# ATSAM4NxC register map
Vendor: Atmel; Series: SAM4N; File version: 0
Atmel ATSAM4NxC Microcontroller
CPU: CM4 r0p1, selectable endian, MPU, no FPU, 4 interrupt priority bits
Registers are 32-bit, read-write, reset 0x0 unless marked. A register's access mark holds for its fields unless they carry their own. Offsets are from the block's base; lines under a group give offsets from that group; [hi:lo] are bit positions; {n}, {i} and the like mark numbered series; 'fields as' and 'values as' point back to an identical list; <NAME> marks a mode.

## Memory map
0x40008000 SPI size 0x4000 — Serial Peripheral Interface
0x4000D000 MPU size 0x830 — Memory Protection Unit (MPU)
0x40010000 TC0 size 0x4000 — Timer Counter 0
0x40014000 TC1 size 0x4000 — Timer Counter 1
0x40018000 TWI0 size 0x4000 — Two-wire Interface 0
0x4001C000 TWI1 size 0x4000 — Two-wire Interface 1
0x40020000 PWM size 0x4000 — Pulse Width Modulation Controller
0x40024000 USART0 size 0x4000 — Universal Synchronous Asynchronous Receiver Transmitter 0
0x40028000 USART1 size 0x4000 — Universal Synchronous Asynchronous Receiver Transmitter 1
0x4002C000 USART2 size 0x4000 — Universal Synchronous Asynchronous Receiver Transmitter 2
0x40038000 ADC size 0x4000 — Analog-to-Digital Converter
0x4003C000 DACC size 0x4000 — Digital-to-Analog Converter Controller
0x40040000 TWI2 size 0x4000 — Two-wire Interface 2
0x40044000 UART2 size 0x4000 — Universal Asynchronous Receiver Transmitter 2
0x40048000 UART3 size 0x4000 — Universal Asynchronous Receiver Transmitter 3
0x400E0200 MATRIX size 0x200 — AHB Bus Matrix
0x400E0400 PMC size 0x140 — Power Management Controller
0x400E0600 UART0 size 0x128 — Universal Asynchronous Receiver Transmitter 0
0x400E0740 CHIPID size 0x200 — Chip Identifier
0x400E0800 UART1 size 0x128 — Universal Asynchronous Receiver Transmitter 1
0x400E0A00 EFC size 0x200 — Embedded Flash Controller
0x400E0E00 PIOA size 0x200 — Parallel Input/Output Controller A
0x400E1000 PIOB size 0x200 — Parallel Input/Output Controller B
0x400E1200 PIOC size 0x200 — Parallel Input/Output Controller C
0x400E1400 RSTC size 0x200 — Reset Controller
0x400E1410 SUPC size 0x200 — Supply Controller
0x400E1430 RTT size 0x200 — Real-time Timer
0x400E1450 WDT size 0x200 — Watchdog Timer
0x400E1460 RTC size 0x200 — Real-time Clock
0x400E1490 GPBR size 0x200 — General Purpose Backup Registers
0xE000E000 SCB blocks up to offset 0xD40 — System Control Block (SCB)
0xE000E010 SYST size 0x10 — System timer, SysTick
0xE000E100 NVIC size 0xE04 — Nested Vectored Interrupt Controller (NVIC)

## Interrupts
3 INT_Hard_Fault (SCB)
4 INT_Mem_Manage_Fault (SCB)
5 INT_Bus_Fault (SCB)
5 PMC
6 EFC
6 INT_Usage_Fault (SCB)
8 UART0
9 UART1
10 UART2
11 INT_SVCall (SCB)
11 PIOA
12 PIOB
13 PIOC
14 INT_PendableSrvReq (SCB)
14 USART0
15 INT_SysTick (SYST)
15 USART1
16 UART3
17 USART2
19 TWI0
20 TWI1
21 SPI
22 TWI2
23 TC0
24 TC1 (TC0)
25 TC2 (TC0)
26 TC3 (TC1)
27 TC4 (TC1)
28 TC5 (TC1)
29 ADC
30 DACC
31 PWM

## PWM — Pulse Width Modulation Controller
Base 0x40020000; register names take the prefix PWM_
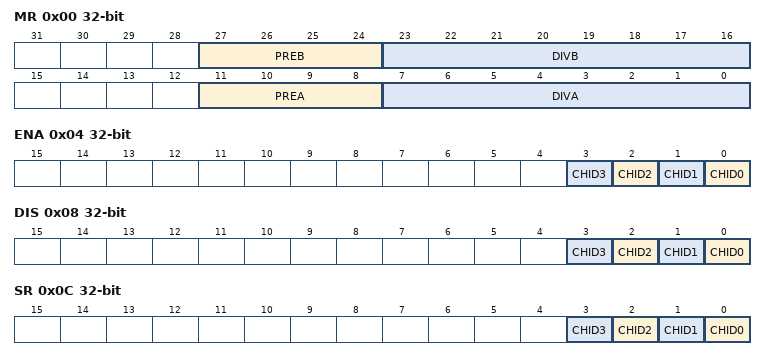
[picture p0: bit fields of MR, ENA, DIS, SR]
0x00 MR — PWM Mode Register
  [27:24] PREB
    0=MCK (Master Clock); 1=MCKDIV2 (Master Clock divided by 2); 2=MCKDIV4 (Master Clock divided by 4); 3=MCKDIV8 (Master Clock divided by 8); 4=MCKDIV16 (Master Clock divided by 16); 5=MCKDIV32 (Master Clock divided by 32); 6=MCKDIV64 (Master Clock divided by 64); 7=MCKDIV128 (Master Clock divided by 128); 8=MCKDIV256 (Master Clock divided by 256); 9=MCKDIV512 (Master Clock divided by 512); 10=MCKDIV1024 (Master Clock divided by 1024)
  [23:16] DIVB — CLKA, CLKB Divide Factor
    0=CLK_OFF (CLKA, CLKB clock is turned off); 1=CLK_DIV1 (CLKA, CLKB clock is clock selected by PREA, PREB)
  [11:8] PREA
    values as PREB
  [7:0] DIVA — CLKA, CLKB Divide Factor
    values as DIVB
0x04 ENA wo reset not defined — PWM Enable Register
  [n] CHID{n} (n=0..3) — Channel ID
0x08 DIS wo reset not defined — PWM Disable Register
  [n] CHID{n} (n=0..3) — Channel ID
0x0C SR ro — PWM Status Register
  [n] CHID{n} (n=0..3) — Channel ID
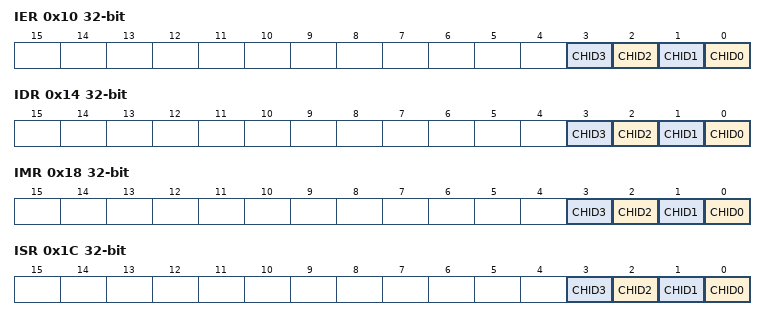
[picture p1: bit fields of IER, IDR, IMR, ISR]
0x10 IER wo reset not defined — PWM Interrupt Enable Register
  [n] CHID{n} (n=0..3) — Channel ID.
0x14 IDR wo reset not defined — PWM Interrupt Disable Register
  [n] CHID{n} (n=0..3) — Channel ID.
0x18 IMR ro — PWM Interrupt Mask Register
  [n] CHID{n} (n=0..3) — Channel ID.
0x1C ISR ro — PWM Interrupt Status Register
  [n] CHID{n} (n=0..3) — Channel ID
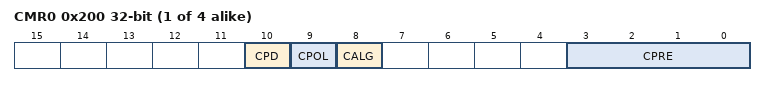
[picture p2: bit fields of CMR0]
{0x200+0x20*i} CMR{i} (i=0..3) — PWM Channel Mode Register (ch_num = {i})
  [10] CPD — Channel Update Period
  [9] CPOL — Channel Polarity
  [8] CALG — Channel Alignment
  [3:0] CPRE — Channel Pre-scaler
    0=MCK (Master Clock); 1=MCKDIV2 (Master Clock divided by 2); 2=MCKDIV4 (Master Clock divided by 4); 3=MCKDIV8 (Master Clock divided by 8); 4=MCKDIV16 (Master Clock divided by 16); 5=MCKDIV32 (Master Clock divided by 32); 6=MCKDIV64 (Master Clock divided by 64); 7=MCKDIV128 (Master Clock divided by 128); 8=MCKDIV256 (Master Clock divided by 256); 9=MCKDIV512 (Master Clock divided by 512); 10=MCKDIV1024 (Master Clock divided by 1024); 11=CLKA (Clock A); 12=CLKB (Clock B)
{0x204+0x20*i} CDTY{i} (i=0..3) — PWM Channel Duty Cycle Register (ch_num = {i})
  [31:0] CDTY — Channel Duty Cycle
{0x208+0x20*i} CPRD{i} (i=0..3) — PWM Channel Period Register (ch_num = {i})
  [31:0] CPRD — Channel Period
{0x20C+0x20*i} CCNT{i} ro (i=0..3) — PWM Channel Counter Register (ch_num = {i})
  [31:0] CNT — Channel Counter Register
{0x210+0x20*i} CUPD{i} wo reset not defined (i=0..3) — PWM Channel Update Register (ch_num = {i})
  [31:0] CUPD

## Notices in the file
SAM Software Package License
Copyright (c) 2014, Atmel Corporation
All rights reserved.
Redistribution and use in source and binary forms, with or without
modification, are permitted provided that the following condition is met:
- Redistributions of source code must retain the above copyright notice,
this list of conditions and the disclaimer below.
Atmel's name may not be used to endorse or promote products derived from
this software without specific prior written permission.
DISCLAIMER:  THIS SOFTWARE IS PROVIDED BY ATMEL "AS IS" AND ANY EXPRESS OR
IMPLIED WARRANTIES, INCLUDING, BUT NOT LIMITED TO, THE IMPLIED WARRANTIES OF
MERCHANTABILITY, FITNESS FOR A PARTICULAR PURPOSE AND NON-INFRINGEMENT ARE
DISCLAIMED. IN NO EVENT SHALL ATMEL BE LIABLE FOR ANY DIRECT, INDIRECT,
INCIDENTAL, SPECIAL, EXEMPLARY, OR CONSEQUENTIAL DAMAGES (INCLUDING, BUT NOT
LIMITED TO, PROCUREMENT OF SUBSTITUTE GOODS OR SERVICES; LOSS OF USE, DATA,
OR PROFITS; OR BUSINESS INTERRUPTION) HOWEVER CAUSED AND ON ANY THEORY OF
LIABILITY, WHETHER IN CONTRACT, STRICT LIABILITY, OR TORT (INCLUDING
NEGLIGENCE OR OTHERWISE) ARISING IN ANY WAY OUT OF THE USE OF THIS SOFTWARE,
EVEN IF ADVISED OF THE POSSIBILITY OF SUCH DAMAGE.
